# COMPUTE_CLUSTER0_CTL_CFG register map
Vendor: Texas Instruments
Registers are 32-bit, read-write, reset 0x0 unless marked. A register's access mark holds for its fields unless they carry their own. Offsets are as the file gives them; [hi:lo] are bit positions; {n}, {i} and the like mark numbered series.

## COMPUTE_CLUSTER0_CTL_CFG (part 3 of 3)
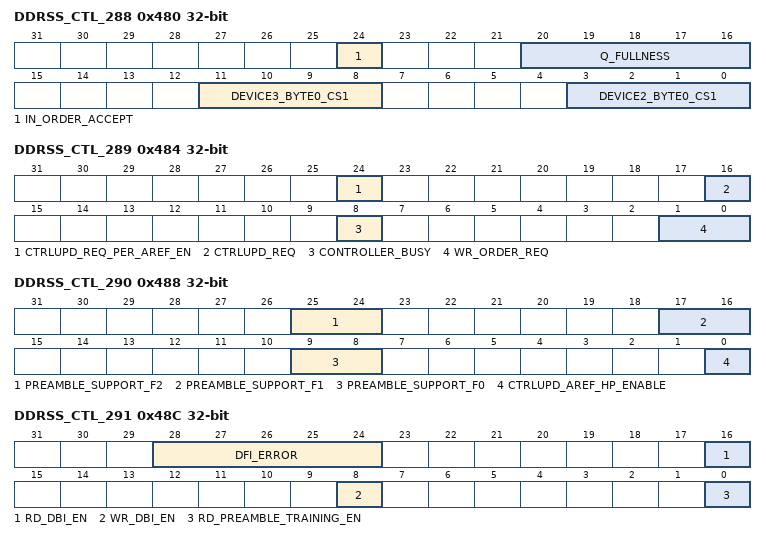
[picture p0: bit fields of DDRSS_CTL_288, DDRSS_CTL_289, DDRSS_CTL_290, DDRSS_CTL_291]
0x480 DDRSS_CTL_288
  [24] IN_ORDER_ACCEPT — Forces the controller to accept commands in the order in which they are placed in the command queue.
  [20:16] Q_FULLNESS — Quantity that determines command queue almost full assertion(q_almost_full).
  [11:8] DEVICE3_BYTE0_CS1 — Defines the byte location of byte0 in the memory datapath for device 3 on chip 1.
  [3:0] DEVICE2_BYTE0_CS1 — Defines the byte location of byte0 in the memory datapath for device 2 on chip 1.
0x484 DDRSS_CTL_289 access per field
  [24] CTRLUPD_REQ_PER_AREF_EN rw — Enable an automatic controller-initiated update (dfi_ctrlupd_req) after every refresh.
  [16] CTRLUPD_REQ wo — Assert the DFI controller-initiated update request signal dfi_ctrlupd_req.
  [8] CONTROLLER_BUSY ro — Indicator that the controller is processing a command.
  [1:0] WR_ORDER_REQ rw — Determines if the controller can re-order write commands from the same source ID and/or the same port.
0x488 DDRSS_CTL_290
  [25:24] PREAMBLE_SUPPORT_F2 — Selection of one or two cycle preamble for read and write burst transfers for frequency copy 2.
  [17:16] PREAMBLE_SUPPORT_F1 — Selection of one or two cycle preamble for read and write burst transfers for frequency copy 1.
  [9:8] PREAMBLE_SUPPORT_F0 — Selection of one or two cycle preamble for read and write burst transfers for frequency copy 0.
  [0] CTRLUPD_AREF_HP_ENABLE — Enable an automatic controller-initiated update (dfi_ctrlupd_req) after every high priority refresh when executing as a subtask request.
0x48C DDRSS_CTL_291 access per field
  [28:24] DFI_ERROR ro — Indicates that the DFI error flag has been asserted.
  [16] RD_DBI_EN rw — Enables controller support of DRAM DBI feature for read data with DDR4 devices.
  [8] WR_DBI_EN rw — Enables controller support of DRAM DBI feature for write data with DDR4 devices.
  [0] RD_PREAMBLE_TRAINING_EN rw — Enable read preamble training during gate training.
0x490 DDRSS_CTL_292 access per field
  [19:0] DFI_ERROR_INFO ro — Holds the encoded DFI error type associated with the DFI_ERROR parameter assertion.
0x494 DDRSS_CTL_293 ro
  [31:0] INT_STATUS_0 — Status of interrupt features in the controller.
0x498 DDRSS_CTL_294 ro
  [12:0] INT_STATUS_1 — Status of interrupt features in the controller.
0x49C DDRSS_CTL_295 wo
  [31:0] INT_ACK_0 — Clear mask of the INT_STATUS parameter.
0x4A0 DDRSS_CTL_296 wo
  [11:0] INT_ACK_1 — Clear mask of the INT_STATUS parameter.
0x4A4 DDRSS_CTL_297
  [31:0] INT_MASK_0 — Mask for the controller_int signal from the INT_STATUS parameter.
0x4A8 DDRSS_CTL_298
  [12:0] INT_MASK_1 — Mask for the controller_int signal from the INT_STATUS parameter.
0x4AC DDRSS_CTL_299 ro
  [31:0] OUT_OF_RANGE_ADDR_0 — Address of command that caused an out-of-range interrupt.
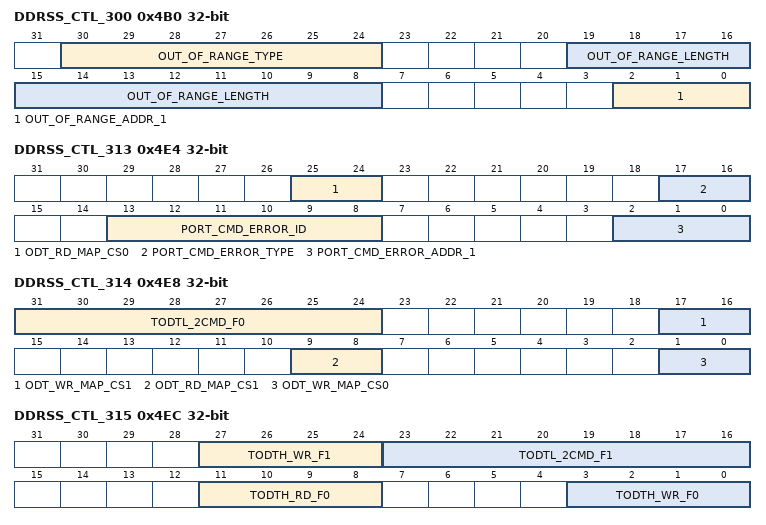
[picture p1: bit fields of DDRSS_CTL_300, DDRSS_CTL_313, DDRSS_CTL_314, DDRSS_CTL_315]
0x4B0 DDRSS_CTL_300 ro
  [30:24] OUT_OF_RANGE_TYPE — Type of command that caused an out-of-range interrupt.
  [19:8] OUT_OF_RANGE_LENGTH — Length of command that caused an out-of-range interrupt.
  [2:0] OUT_OF_RANGE_ADDR_1 — Address of command that caused an out-of-range interrupt.
0x4B4 DDRSS_CTL_301 ro
  [5:0] OUT_OF_RANGE_SOURCE_ID — Source ID of command that caused an out-of-range interrupt.
{0x0+4i} DDRSS_CTL_{i} ro (i=302..305)
  [31:0] BIST_EXP_DATA_{i-302} — Expected data on BIST error.
{0x0+4i} DDRSS_CTL_{i} ro (i=306..309)
  [31:0] BIST_FAIL_DATA_{i-306} — Actual data on BIST error.
0x4D8 DDRSS_CTL_310 ro
  [31:0] BIST_FAIL_ADDR_0 — Address of BIST error.
0x4DC DDRSS_CTL_311 ro
  [2:0] BIST_FAIL_ADDR_1 — Address of BIST error.
0x4E0 DDRSS_CTL_312 ro
  [31:0] PORT_CMD_ERROR_ADDR_0 — Address of command that caused the PORT command error.
0x4E4 DDRSS_CTL_313 access per field
  [25:24] ODT_RD_MAP_CS0 rw — Determines which chip(s) will have termination when a read occurs on chip select 0.
  [17:16] PORT_CMD_ERROR_TYPE ro — Type of error and access type that caused the PORT command error.
  [13:8] PORT_CMD_ERROR_ID ro — Source ID of command that caused the PORT command error.
  [2:0] PORT_CMD_ERROR_ADDR_1 ro — Address of command that caused the PORT command error.
0x4E8 DDRSS_CTL_314
  [31:24] TODTL_2CMD_F0 — Defines the DRAM delay from an ODT de-assertion to the next non-write, non-read command.
  [17:16] ODT_WR_MAP_CS1 — Determines which chip(s) will have termination when a write occurs on chip select 1.
  [9:8] ODT_RD_MAP_CS1 — Determines which chip(s) will have termination when a read occurs on chip select 1.
  [1:0] ODT_WR_MAP_CS0 — Determines which chip(s) will have termination when a write occurs on chip select 0.
0x4EC DDRSS_CTL_315
  [27:24] TODTH_WR_F1 — Defines the DRAM minimum ODT high time after an ODT assertion for a write command.
  [23:16] TODTL_2CMD_F1 — Defines the DRAM delay from an ODT de-assertion to the next non-write, non-read command.
  [11:8] TODTH_RD_F0 — Defines the DRAM minimum ODT high time after an ODT assertion for a read command.
  [3:0] TODTH_WR_F0 — Defines the DRAM minimum ODT high time after an ODT assertion for a write command.
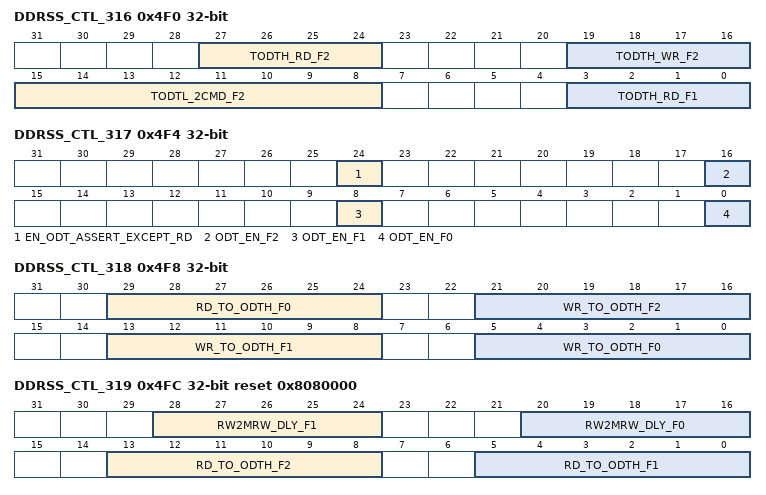
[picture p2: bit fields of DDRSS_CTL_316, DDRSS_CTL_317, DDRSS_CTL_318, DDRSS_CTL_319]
0x4F0 DDRSS_CTL_316
  [27:24] TODTH_RD_F2 — Defines the DRAM minimum ODT high time after an ODT assertion for a read command.
  [19:16] TODTH_WR_F2 — Defines the DRAM minimum ODT high time after an ODT assertion for a write command.
  [15:8] TODTL_2CMD_F2 — Defines the DRAM delay from an ODT de-assertion to the next non-write, non-read command.
  [3:0] TODTH_RD_F1 — Defines the DRAM minimum ODT high time after an ODT assertion for a read command.
0x4F4 DDRSS_CTL_317
  [24] EN_ODT_ASSERT_EXCEPT_RD — Enable controller to assert ODT at all times except during reads.
  [16] ODT_EN_F2 — Enable support of DRAM ODT.
  [8] ODT_EN_F1 — Enable support of DRAM ODT.
  [0] ODT_EN_F0 — Enable support of DRAM ODT.
0x4F8 DDRSS_CTL_318
  [29:24] RD_TO_ODTH_F0 — Defines the delay from a read command to ODT assertion.
  [21:16] WR_TO_ODTH_F2 — Defines the delay from a write command to ODT assertion.
  [13:8] WR_TO_ODTH_F1 — Defines the delay from a write command to ODT assertion.
  [5:0] WR_TO_ODTH_F0 — Defines the delay from a write command to ODT assertion.
0x4FC DDRSS_CTL_319 reset 0x8080000
  [28:24] RW2MRW_DLY_F1 — Additional delay to insert between read or write and mode_reg_write.
  [20:16] RW2MRW_DLY_F0 — Additional delay to insert between read or write and mode_reg_write.
  [13:8] RD_TO_ODTH_F2 — Defines the delay from a read command to ODT assertion.
  [5:0] RD_TO_ODTH_F1 — Defines the delay from a read command to ODT assertion.
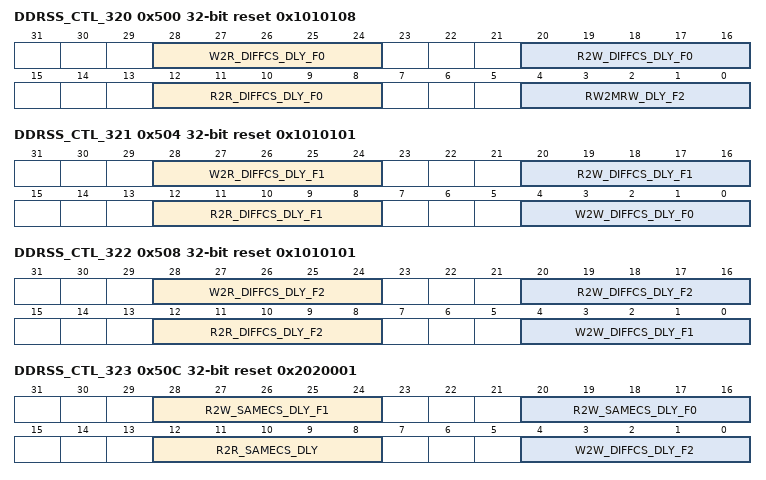
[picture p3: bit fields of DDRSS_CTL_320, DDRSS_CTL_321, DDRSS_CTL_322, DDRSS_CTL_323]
0x500 DDRSS_CTL_320 reset 0x1010108
  [28:24] W2R_DIFFCS_DLY_F0 — Additional delay to insert between writes and reads to different chip selects.
  [20:16] R2W_DIFFCS_DLY_F0 — Additional delay to insert between reads and writes to different chip selects.
  [12:8] R2R_DIFFCS_DLY_F0 — Additional delay to insert between reads to different chip selects.
  [4:0] RW2MRW_DLY_F2 — Additional delay to insert between read or write and mode_reg_write.
0x504 DDRSS_CTL_321 reset 0x1010101
  [28:24] W2R_DIFFCS_DLY_F1 — Additional delay to insert between writes and reads to different chip selects.
  [20:16] R2W_DIFFCS_DLY_F1 — Additional delay to insert between reads and writes to different chip selects.
  [12:8] R2R_DIFFCS_DLY_F1 — Additional delay to insert between reads to different chip selects.
  [4:0] W2W_DIFFCS_DLY_F0 — Additional delay to insert between writes to different chip selects.
0x508 DDRSS_CTL_322 reset 0x1010101
  [28:24] W2R_DIFFCS_DLY_F2 — Additional delay to insert between writes and reads to different chip selects.
  [20:16] R2W_DIFFCS_DLY_F2 — Additional delay to insert between reads and writes to different chip selects.
  [12:8] R2R_DIFFCS_DLY_F2 — Additional delay to insert between reads to different chip selects.
  [4:0] W2W_DIFFCS_DLY_F1 — Additional delay to insert between writes to different chip selects.
0x50C DDRSS_CTL_323 reset 0x2020001
  [28:24] R2W_SAMECS_DLY_F1 — Additional delay to insert between reads and writes to the same chip select.
  [20:16] R2W_SAMECS_DLY_F0 — Additional delay to insert between reads and writes to the same chip select.
  [12:8] R2R_SAMECS_DLY — Additional delay to insert between two reads to the same chip select.
  [4:0] W2W_DIFFCS_DLY_F2 — Additional delay to insert between writes to different chip selects.
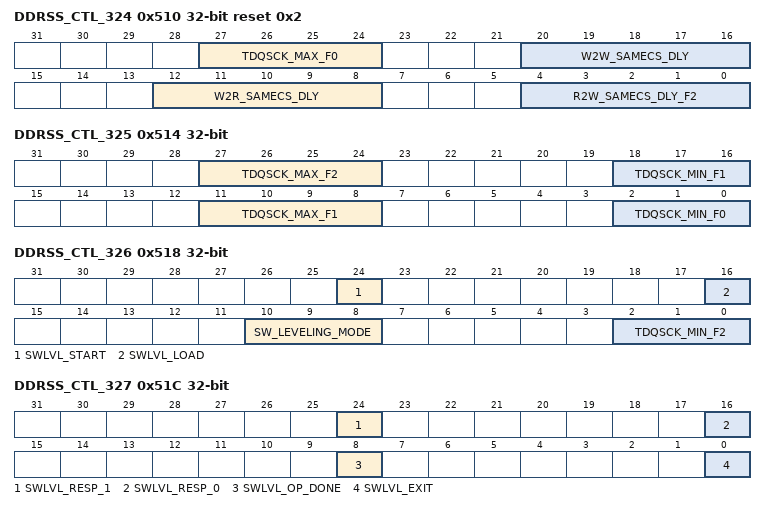
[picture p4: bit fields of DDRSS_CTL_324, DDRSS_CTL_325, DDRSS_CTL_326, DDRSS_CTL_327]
0x510 DDRSS_CTL_324 reset 0x2
  [27:24] TDQSCK_MAX_F0 — Additional delay needed for tDQSCK.
  [20:16] W2W_SAMECS_DLY — Additional delay to insert between two writes to the same chip select.
  [12:8] W2R_SAMECS_DLY — Additional delay to insert between writes and reads to the same chip select.
  [4:0] R2W_SAMECS_DLY_F2 — Additional delay to insert between reads and writes to the same chip select.
0x514 DDRSS_CTL_325
  [27:24] TDQSCK_MAX_F2 — Additional delay needed for tDQSCK.
  [18:16] TDQSCK_MIN_F1 — Additional delay needed for tDQSCK.
  [11:8] TDQSCK_MAX_F1 — Additional delay needed for tDQSCK.
  [2:0] TDQSCK_MIN_F0 — Additional delay needed for tDQSCK.
0x518 DDRSS_CTL_326 access per field
  [24] SWLVL_START wo — User request to initiate software leveling of type in the SW_LEVELING_MODE parameter.
  [16] SWLVL_LOAD wo — User request to load delays and execute software leveling.
  [10:8] SW_LEVELING_MODE rw — Defines the leveling operation for software leveling.
  [2:0] TDQSCK_MIN_F2 rw — Additional delay needed for tDQSCK.
0x51C DDRSS_CTL_327 access per field
  [24] SWLVL_RESP_1 ro — Leveling response for data slice 1.
  [16] SWLVL_RESP_0 ro — Leveling response for data slice 0.
  [8] SWLVL_OP_DONE ro — Signals that software leveling is currently in progress.
  [0] SWLVL_EXIT wo — User request to exit software leveling.
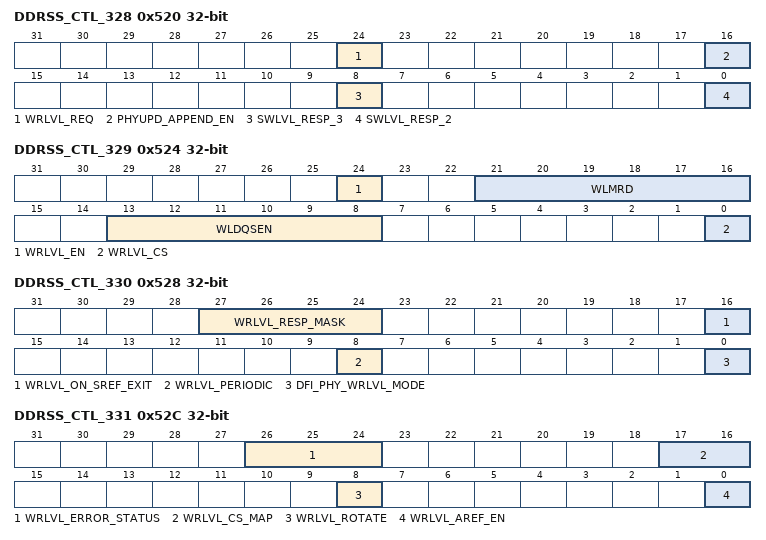
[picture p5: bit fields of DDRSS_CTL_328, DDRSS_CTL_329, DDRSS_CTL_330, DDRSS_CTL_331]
0x520 DDRSS_CTL_328 access per field
  [24] WRLVL_REQ wo — User request to initiate write leveling.
  [16] PHYUPD_APPEND_EN rw — Specifies if a PHY update will be run prior to completing a training sequence.
  [8] SWLVL_RESP_3 ro — Leveling response for data slice 3.
  [0] SWLVL_RESP_2 ro — Leveling response for data slice 2.
0x524 DDRSS_CTL_329
  [24] WRLVL_EN — Enable the MC write leveling module.
  [21:16] WLMRD — Delay from issuing MRS to first write leveling strobe.
  [13:8] WLDQSEN — Delay from issuing MRS to first DQS strobe for write leveling.
  [0] WRLVL_CS — Specifies the target chip select for the write leveling operation initiated through the WRLVL_REQ parameter.
0x528 DDRSS_CTL_330
  [27:24] WRLVL_RESP_MASK — Mask for the dfi_wrlvl_resp signal during write leveling.
  [16] WRLVL_ON_SREF_EXIT — Enables automatic write leveling on a self-refresh exit.
  [8] WRLVL_PERIODIC — Enables the use of the dfi_lvl_periodic signal during write leveling.
  [0] DFI_PHY_WRLVL_MODE — Specifies the PHY support for DFI write leveling.
0x52C DDRSS_CTL_331 access per field
  [26:24] WRLVL_ERROR_STATUS ro — Holds the error associated with the write level error interrupt.
  [17:16] WRLVL_CS_MAP rw — Defines the chip select map for write leveling operations.
  [8] WRLVL_ROTATE rw — Enables rotational CS for interval write leveling.
  [0] WRLVL_AREF_EN rw — Enables refreshes and other non-data commands to execute in the middle of write leveling.
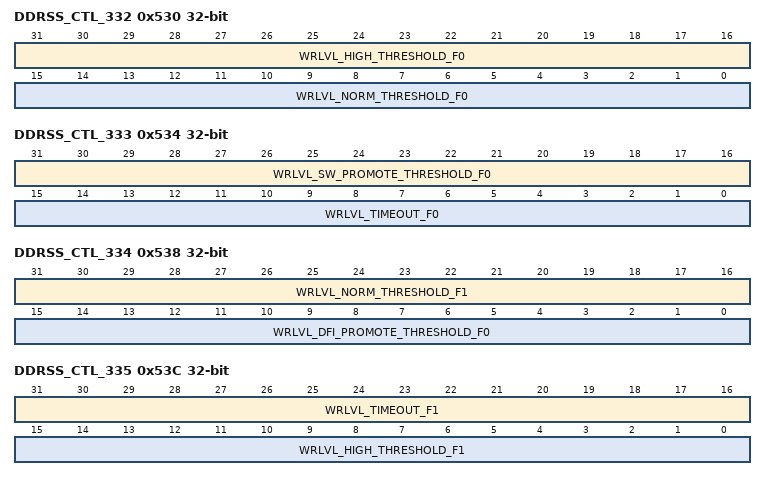
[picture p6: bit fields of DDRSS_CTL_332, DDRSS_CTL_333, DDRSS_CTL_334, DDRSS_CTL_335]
0x530 DDRSS_CTL_332
  [31:16] WRLVL_HIGH_THRESHOLD_F0 — Write leveling high threshold number of long counts until the high priority request is asserted.
  [15:0] WRLVL_NORM_THRESHOLD_F0 — Write leveling normal threshold number of long counts until the normal priority request is asserted.
0x534 DDRSS_CTL_333
  [31:16] WRLVL_SW_PROMOTE_THRESHOLD_F0 — Write leveling promotion number of long counts until the high priority request is asserted.
  [15:0] WRLVL_TIMEOUT_F0 — Write leveling timeout number of long counts until the timeout is asserted.
0x538 DDRSS_CTL_334
  [31:16] WRLVL_NORM_THRESHOLD_F1 — Write leveling normal threshold number of long counts until the normal priority request is asserted.
  [15:0] WRLVL_DFI_PROMOTE_THRESHOLD_F0 — Write leveling promotion number of long counts until the high priority request is asserted.
0x53C DDRSS_CTL_335
  [31:16] WRLVL_TIMEOUT_F1 — Write leveling timeout number of long counts until the timeout is asserted.
  [15:0] WRLVL_HIGH_THRESHOLD_F1 — Write leveling high threshold number of long counts until the high priority request is asserted.
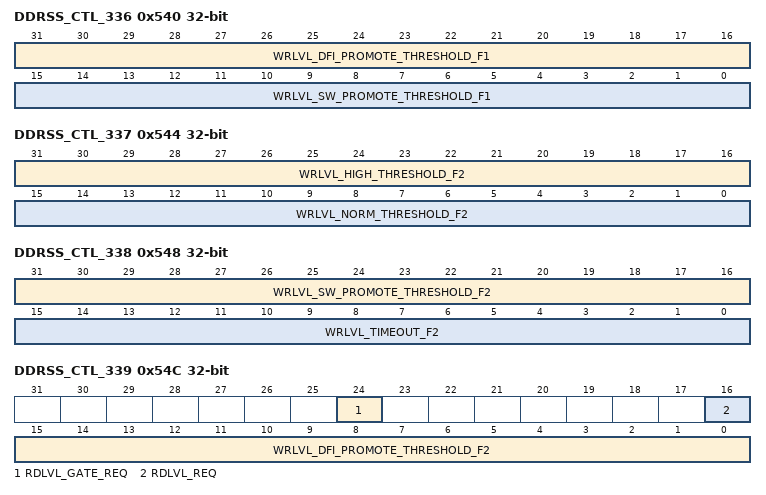
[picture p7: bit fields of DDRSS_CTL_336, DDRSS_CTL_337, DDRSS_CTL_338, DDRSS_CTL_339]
0x540 DDRSS_CTL_336
  [31:16] WRLVL_DFI_PROMOTE_THRESHOLD_F1 — Write leveling promotion number of long counts until the high priority request is asserted.
  [15:0] WRLVL_SW_PROMOTE_THRESHOLD_F1 — Write leveling promotion number of long counts until the high priority request is asserted.
0x544 DDRSS_CTL_337
  [31:16] WRLVL_HIGH_THRESHOLD_F2 — Write leveling high threshold number of long counts until the high priority request is asserted.
  [15:0] WRLVL_NORM_THRESHOLD_F2 — Write leveling normal threshold number of long counts until the normal priority request is asserted.
0x548 DDRSS_CTL_338
  [31:16] WRLVL_SW_PROMOTE_THRESHOLD_F2 — Write leveling promotion number of long counts until the high priority request is asserted.
  [15:0] WRLVL_TIMEOUT_F2 — Write leveling timeout number of long counts until the timeout is asserted.
0x54C DDRSS_CTL_339 access per field
  [24] RDLVL_GATE_REQ wo — User request to initiate gate training.
  [16] RDLVL_REQ wo — User request to initiate data eye training.
  [15:0] WRLVL_DFI_PROMOTE_THRESHOLD_F2 rw — Write leveling promotion number of long counts until the high priority request is asserted.
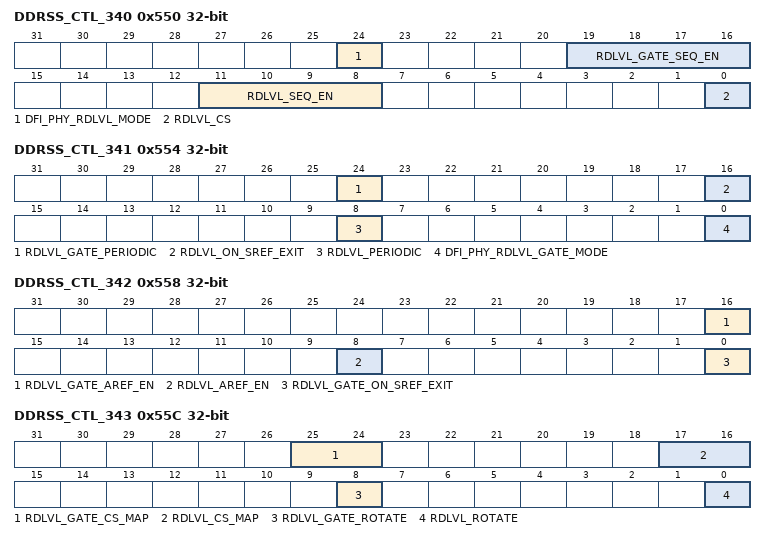
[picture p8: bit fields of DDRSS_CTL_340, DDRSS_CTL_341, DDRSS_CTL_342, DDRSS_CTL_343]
0x550 DDRSS_CTL_340
  [24] DFI_PHY_RDLVL_MODE — Specifies the PHY support for DFI data eye training.
  [19:16] RDLVL_GATE_SEQ_EN — Specifies the pattern, format and MPR for gate training.
  [11:8] RDLVL_SEQ_EN — Specifies the pattern, format and MPR for data eye training.
  [0] RDLVL_CS — Specifies the target chip select for the data eye training operation initiated through the RDLVL_REQ parameter or the gate training operation initiated through the RDLVL_GATE_REQ parameter.
0x554 DDRSS_CTL_341
  [24] RDLVL_GATE_PERIODIC — Enables the use of the dfi_lvl_periodic signal during gate training.
  [16] RDLVL_ON_SREF_EXIT — Enables automatic data eye training on a self-refresh exit.
  [8] RDLVL_PERIODIC — Enables the use of the dfi_lvl_periodic signal during data eye training.
  [0] DFI_PHY_RDLVL_GATE_MODE — Specifies the PHY support for DFI gate training.
0x558 DDRSS_CTL_342
  [16] RDLVL_GATE_AREF_EN — Enables refreshes and other non-data commands to execute in the middle of gate training.
  [8] RDLVL_AREF_EN — Enables refreshes and other non-data commands to execute in the middle of data eye training.
  [0] RDLVL_GATE_ON_SREF_EXIT — Enables automatic gate training on a self-refresh exit.
0x55C DDRSS_CTL_343
  [25:24] RDLVL_GATE_CS_MAP — Defines the chip select map for gate training operations.
  [17:16] RDLVL_CS_MAP — Defines the chip select map for data eye training operations.
  [8] RDLVL_GATE_ROTATE — Enables rotational CS for interval gate training.
  [0] RDLVL_ROTATE — Enables rotational CS for interval data eye training.
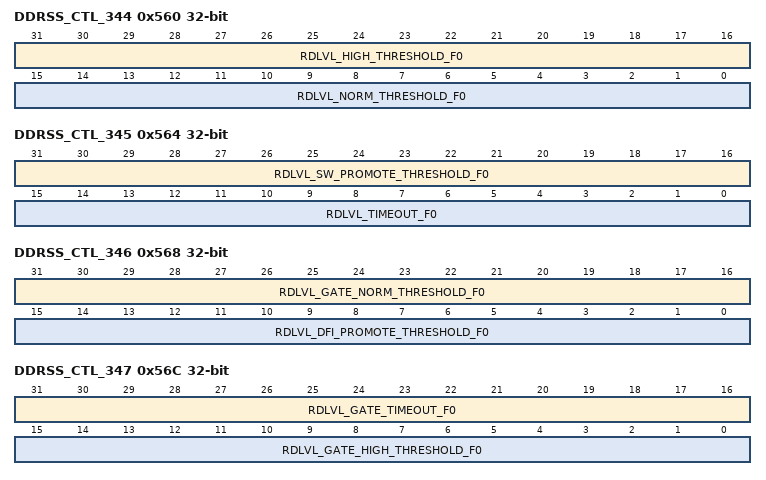
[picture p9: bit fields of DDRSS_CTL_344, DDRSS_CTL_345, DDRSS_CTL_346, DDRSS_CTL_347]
0x560 DDRSS_CTL_344
  [31:16] RDLVL_HIGH_THRESHOLD_F0 — Read leveling high threshold number of long counts until the high priority request is asserted.
  [15:0] RDLVL_NORM_THRESHOLD_F0 — Read leveling normal threshold number of long counts until the normal priority request is asserted.
0x564 DDRSS_CTL_345
  [31:16] RDLVL_SW_PROMOTE_THRESHOLD_F0 — Read leveling promotion number of long counts until the high priority request is asserted.
  [15:0] RDLVL_TIMEOUT_F0 — Read leveling timeout number of long counts until the timeout is asserted.
0x568 DDRSS_CTL_346
  [31:16] RDLVL_GATE_NORM_THRESHOLD_F0 — Gate training normal threshold number of long counts until the normal priority request is asserted.
  [15:0] RDLVL_DFI_PROMOTE_THRESHOLD_F0 — Read leveling promotion number of long counts until the high priority request is asserted.
0x56C DDRSS_CTL_347
  [31:16] RDLVL_GATE_TIMEOUT_F0 — Gate training timeout number of long counts until the timeout is asserted.
  [15:0] RDLVL_GATE_HIGH_THRESHOLD_F0 — Gate training high threshold number of long counts until the high priority request is asserted.
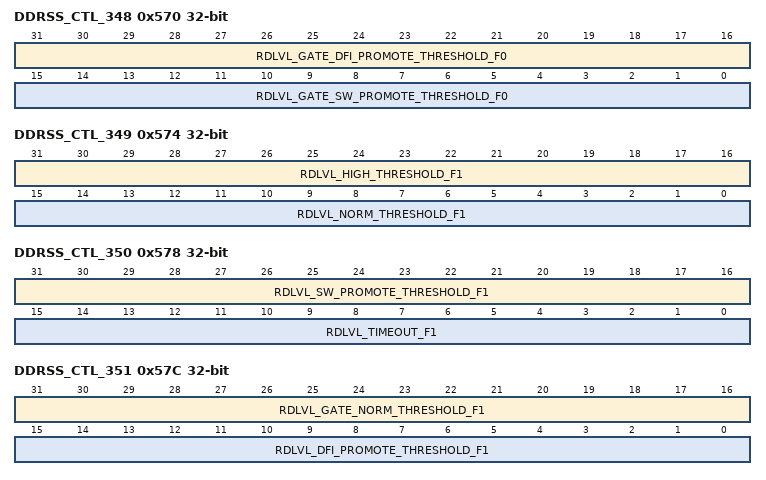
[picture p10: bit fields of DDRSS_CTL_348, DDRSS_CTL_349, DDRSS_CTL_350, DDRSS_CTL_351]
0x570 DDRSS_CTL_348
  [31:16] RDLVL_GATE_DFI_PROMOTE_THRESHOLD_F0 — Gate training promotion number of long counts until the high priority request is asserted.
  [15:0] RDLVL_GATE_SW_PROMOTE_THRESHOLD_F0 — Gate training promotion number of long counts until the high priority request is asserted.
0x574 DDRSS_CTL_349
  [31:16] RDLVL_HIGH_THRESHOLD_F1 — Read leveling high threshold number of long counts until the high priority request is asserted.
  [15:0] RDLVL_NORM_THRESHOLD_F1 — Read leveling normal threshold number of long counts until the normal priority request is asserted.
0x578 DDRSS_CTL_350
  [31:16] RDLVL_SW_PROMOTE_THRESHOLD_F1 — Read leveling promotion number of long counts until the high priority request is asserted.
  [15:0] RDLVL_TIMEOUT_F1 — Read leveling timeout number of long counts until the timeout is asserted.
0x57C DDRSS_CTL_351
  [31:16] RDLVL_GATE_NORM_THRESHOLD_F1 — Gate training normal threshold number of long counts until the normal priority request is asserted.
  [15:0] RDLVL_DFI_PROMOTE_THRESHOLD_F1 — Read leveling promotion number of long counts until the high priority request is asserted.
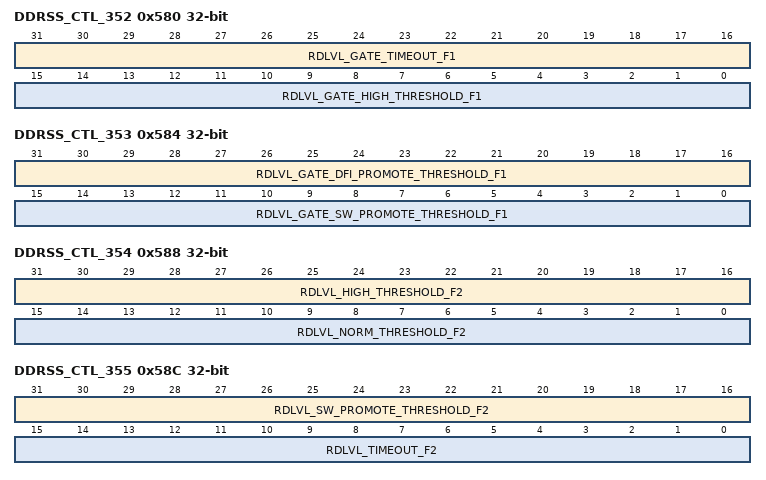
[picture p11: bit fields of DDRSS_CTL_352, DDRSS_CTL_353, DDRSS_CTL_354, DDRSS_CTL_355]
0x580 DDRSS_CTL_352
  [31:16] RDLVL_GATE_TIMEOUT_F1 — Gate training timeout number of long counts until the timeout is asserted.
  [15:0] RDLVL_GATE_HIGH_THRESHOLD_F1 — Gate training high threshold number of long counts until the high priority request is asserted.
0x584 DDRSS_CTL_353
  [31:16] RDLVL_GATE_DFI_PROMOTE_THRESHOLD_F1 — Gate training promotion number of long counts until the high priority request is asserted.
  [15:0] RDLVL_GATE_SW_PROMOTE_THRESHOLD_F1 — Gate training promotion number of long counts until the high priority request is asserted.
0x588 DDRSS_CTL_354
  [31:16] RDLVL_HIGH_THRESHOLD_F2 — Read leveling high threshold number of long counts until the high priority request is asserted.
  [15:0] RDLVL_NORM_THRESHOLD_F2 — Read leveling normal threshold number of long counts until the normal priority request is asserted.
0x58C DDRSS_CTL_355
  [31:16] RDLVL_SW_PROMOTE_THRESHOLD_F2 — Read leveling promotion number of long counts until the high priority request is asserted.
  [15:0] RDLVL_TIMEOUT_F2 — Read leveling timeout number of long counts until the timeout is asserted.
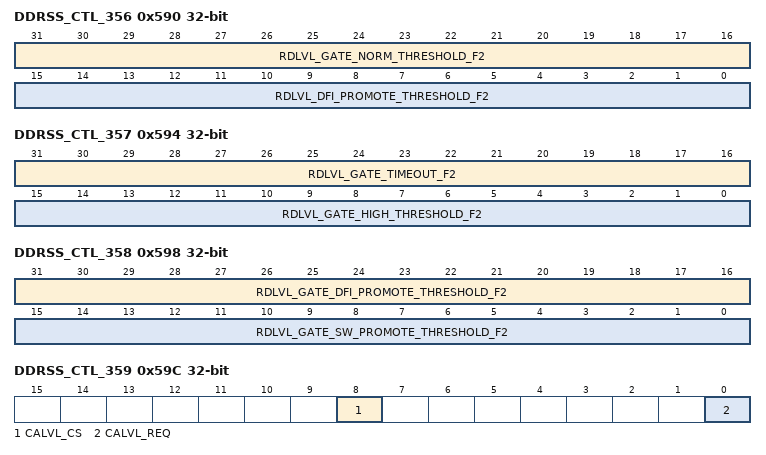
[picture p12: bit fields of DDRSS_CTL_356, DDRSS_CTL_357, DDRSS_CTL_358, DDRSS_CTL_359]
0x590 DDRSS_CTL_356
  [31:16] RDLVL_GATE_NORM_THRESHOLD_F2 — Gate training normal threshold number of long counts until the normal priority request is asserted.
  [15:0] RDLVL_DFI_PROMOTE_THRESHOLD_F2 — Read leveling promotion number of long counts until the high priority request is asserted.
0x594 DDRSS_CTL_357
  [31:16] RDLVL_GATE_TIMEOUT_F2 — Gate training timeout number of long counts until the timeout is asserted.
  [15:0] RDLVL_GATE_HIGH_THRESHOLD_F2 — Gate training high threshold number of long counts until the high priority request is asserted.
0x598 DDRSS_CTL_358
  [31:16] RDLVL_GATE_DFI_PROMOTE_THRESHOLD_F2 — Gate training promotion number of long counts until the high priority request is asserted.
  [15:0] RDLVL_GATE_SW_PROMOTE_THRESHOLD_F2 — Gate training promotion number of long counts until the high priority request is asserted.
0x59C DDRSS_CTL_359 access per field
  [8] CALVL_CS rw — Specifies the target chip select for the CA training operation initiated through the CALVL_REQ parameter.
  [0] CALVL_REQ wo — User request to initiate CA training.
0x5A0 DDRSS_CTL_360
  [19:0] CALVL_PAT_0 — CA Training pattern 0 driven on the CA bus during a calibration command.
0x5A4 DDRSS_CTL_361
  [19:0] CALVL_BG_PAT_0 — CA Training pattern 0 driven on the CA bus before and after a calibration command.
0x5A8 DDRSS_CTL_362
  [19:0] CALVL_PAT_1 — CA Training pattern 1 driven on the CA bus during a calibration command.
0x5AC DDRSS_CTL_363
  [19:0] CALVL_BG_PAT_1 — CA Training pattern 1 driven on the CA bus before and after a calibration command.
0x5B0 DDRSS_CTL_364
  [19:0] CALVL_PAT_2 — CA Training pattern 2 driven on the CA bus during a calibration command.
0x5B4 DDRSS_CTL_365
  [19:0] CALVL_BG_PAT_2 — CA Training pattern 2 driven on the CA bus before and after a calibration command.
0x5B8 DDRSS_CTL_366
  [19:0] CALVL_PAT_3 — CA Training pattern 3 driven on the CA bus during a calibration command.
0x5BC DDRSS_CTL_367
  [19:0] CALVL_BG_PAT_3 — CA Training pattern 3 driven on the CA bus before and after a calibration command.
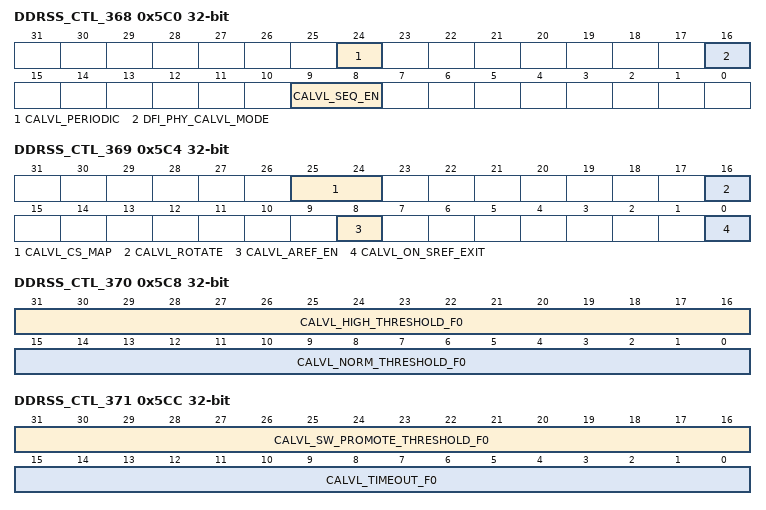
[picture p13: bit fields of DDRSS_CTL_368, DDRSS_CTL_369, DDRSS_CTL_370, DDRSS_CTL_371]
0x5C0 DDRSS_CTL_368
  [24] CALVL_PERIODIC — Enables the use of the dfi_lvl_periodic signal during CA training.
  [16] DFI_PHY_CALVL_MODE — Specifies the PHY support for DFI CA training.
  [9:8] CALVL_SEQ_EN — Specifies which CA training patterns will be used.
0x5C4 DDRSS_CTL_369
  [25:24] CALVL_CS_MAP — Defines the chip select map for CA training operations.
  [16] CALVL_ROTATE — Enables rotational CS for interval CA training.
  [8] CALVL_AREF_EN — Enables refreshes and other non-data commands to execute in the middle of CA training.
  [0] CALVL_ON_SREF_EXIT — Enables automatic CA training on a self-refresh exit.
0x5C8 DDRSS_CTL_370
  [31:16] CALVL_HIGH_THRESHOLD_F0 — CA training high threshold number of long counts until the high priority request is asserted.
  [15:0] CALVL_NORM_THRESHOLD_F0 — CA training normal threshold number of long counts until the normal priority request is asserted.
0x5CC DDRSS_CTL_371
  [31:16] CALVL_SW_PROMOTE_THRESHOLD_F0 — CA training promotion number of long counts until the high priority request is asserted.
  [15:0] CALVL_TIMEOUT_F0 — CA training timeout number of long counts until the timeout is asserted.
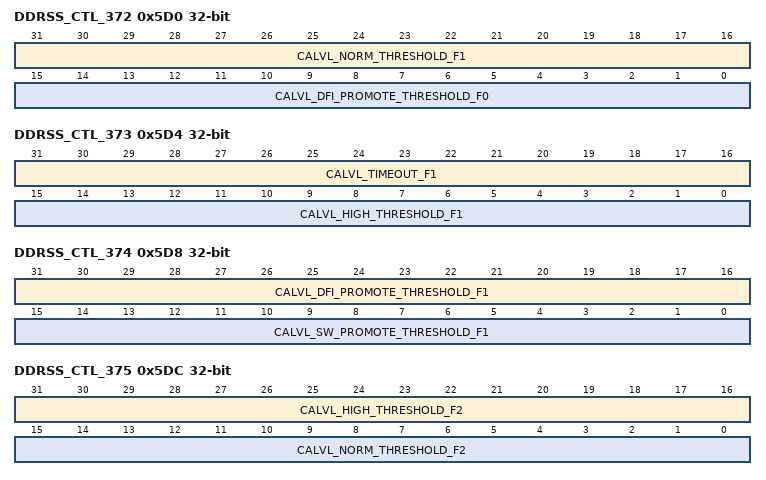
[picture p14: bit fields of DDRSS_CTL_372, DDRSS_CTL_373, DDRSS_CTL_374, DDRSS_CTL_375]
0x5D0 DDRSS_CTL_372
  [31:16] CALVL_NORM_THRESHOLD_F1 — CA training normal threshold number of long counts until the normal priority request is asserted.
  [15:0] CALVL_DFI_PROMOTE_THRESHOLD_F0 — CA training promotion number of long counts until the high priority request is asserted.
0x5D4 DDRSS_CTL_373
  [31:16] CALVL_TIMEOUT_F1 — CA training timeout number of long counts until the timeout is asserted.
  [15:0] CALVL_HIGH_THRESHOLD_F1 — CA training high threshold number of long counts until the high priority request is asserted.
0x5D8 DDRSS_CTL_374
  [31:16] CALVL_DFI_PROMOTE_THRESHOLD_F1 — CA training promotion number of long counts until the high priority request is asserted.
  [15:0] CALVL_SW_PROMOTE_THRESHOLD_F1 — CA training promotion number of long counts until the high priority request is asserted.
0x5DC DDRSS_CTL_375
  [31:16] CALVL_HIGH_THRESHOLD_F2 — CA training high threshold number of long counts until the high priority request is asserted.
  [15:0] CALVL_NORM_THRESHOLD_F2 — CA training normal threshold number of long counts until the normal priority request is asserted.
0x5E0 DDRSS_CTL_376
  [31:16] CALVL_SW_PROMOTE_THRESHOLD_F2 — CA training promotion number of long counts until the high priority request is asserted.
  [15:0] CALVL_TIMEOUT_F2 — CA training timeout number of long counts until the timeout is asserted.
0x5E4 DDRSS_CTL_377
  [24] AXI0_FIXED_PORT_PRIORITY_ENABLE — Defines the priority control for AXI port 0 as per-port or per-command.
  [16] AXI0_ALL_STROBES_USED_ENABLE — Enables use of the AWALLSTRB signal for AXI port 0.
  [15:0] CALVL_DFI_PROMOTE_THRESHOLD_F2 — CA training promotion number of long counts until the high priority request is asserted.
0x5E8 DDRSS_CTL_378
  [10:8] AXI0_W_PRIORITY — Priority of write commands from AXI port 0.
  [2:0] AXI0_R_PRIORITY — Priority of read commands from AXI port 0.
0x5EC DDRSS_CTL_379 ro
  [31:0] PARITY_ERROR_ADDRESS_0 — Address of the AXI command that resulted in the parity error.
0x5F0 DDRSS_CTL_380 ro
  [28:16] PARITY_ERROR_BUS_CHANNEL — Reports the AXI field that resulted in the parity error.
  [13:8] PARITY_ERROR_MASTER_ID — Port ID and Master ID of the AXI command that resulted in the parity error.
  [2:0] PARITY_ERROR_ADDRESS_1 — Address of the AXI command that resulted in the parity error.
{0x0+4i} DDRSS_CTL_{i} ro (i=381..384)
  [31:0] PARITY_ERROR_WRITE_DATA_{i-381} — Write data of the AXI command that resulted in the parity error.
0x604 DDRSS_CTL_385 ro
  [24] MEM_RST_VALID — Register access to mem_rst_valid signal.
  [17:16] CKE_STATUS — Register access to cke_status signal.
  [15:0] PARITY_ERROR_WRITE_DATA_PARITY_VECTOR — Write data parity vector associated with the AXI command that resulted in the parity error.
0x608 DDRSS_CTL_386 access per field
  [30:24] TDFI_PHY_WRLAT ro — Holds the calculated DFI tPHY_WRLAT timing parameter (in DFI PHY clocks), the maximum cycles between a write command and a dfi_wrdata_en assertion.
  [23:16] DLL_RST_ADJ_DLY rw — Minimum cycles after setting master delay in DLL until the DLL reset signal dll_rst_n may be asserted.
  [15:0] DLL_RST_DELAY rw — Minimum cycles required for DLL reset signal dll_rst_n to be held.
0x60C DDRSS_CTL_387 access per field reset 0x6060600
  [30:24] TDFI_PHY_RDLAT_F2 rw — Defines the DFI tPHY_RDLAT timing parameter (in DFI PHY clocks), the maximum cycles between a dfi_rddata_en assertion and a dfi_rddata_valid assertion.
  [22:16] TDFI_PHY_RDLAT_F1 rw — Defines the DFI tPHY_RDLAT timing parameter (in DFI PHY clocks), the maximum cycles between a dfi_rddata_en assertion and a dfi_rddata_valid assertion.
  [14:8] TDFI_PHY_RDLAT_F0 rw — Defines the DFI tPHY_RDLAT timing parameter (in DFI PHY clocks), the maximum cycles between a dfi_rddata_en assertion and a dfi_rddata_valid assertion.
  [6:0] UPDATE_ERROR_STATUS ro — Identifies the source of any DFI MC-initiated or PHY-initiated update errors.
0x610 DDRSS_CTL_388 access per field
  [23:16] TDFI_CTRLUPD_MIN rw — Defines the DFI tCTRLUPD_MIN timing parameter (in DFI clocks), the minimum cycles that dfi_ctrlupd_req must be asserted.
  [9:8] DRAM_CLK_DISABLE rw — Set value for the dfi_dram_clk_disable signal.
  [6:0] TDFI_RDDATA_EN ro — Holds the calculated DFI tRDDATA_EN timing parameter (in DFI PHY clocks), the maximum cycles between a read command and a dfi_rddata_en assertion.
0x614 DDRSS_CTL_389
  [20:0] TDFI_CTRLUPD_MAX_F0 — Defines the DFI tCTRLUPD_MAX timing parameter (in DFI clocks), the maximum cycles that dfi_ctrlupd_req can be asserted.
{0x0+4i} DDRSS_CTL_{i} (i=390..393)
  [31:0] TDFI_PHYUPD_TYPE{i-390}_F0 — Defines the DFI tPHYUPD_TYPE{i-390} timing parameter (in DFI clocks), the maximum cycles that dfi_phyupd_req can assert after dfi_phyupd_ack for dfi_phyupd_type {i-390}.
0x628 DDRSS_CTL_394
  [22:0] TDFI_PHYUPD_RESP_F0 — Defines the DFI tPHYUPD_RESP timing parameter (in DFI clocks), the maximum cycles between a dfi_phyupd_req assertion and a dfi_phyupd_ack assertion.
0x62C DDRSS_CTL_395
  [31:0] TDFI_CTRLUPD_INTERVAL_F0 — Defines the DFI tCTRLUPD_INTERVAL timing parameter (in DFI clocks), the maximum cycles between dfi_ctrlupd_req assertions.
0x630 DDRSS_CTL_396
  [14:8] WRLAT_ADJ_F0 — Adjustment value for PHY write timing.
  [6:0] RDLAT_ADJ_F0 — Adjustment value for PHY read timing.
0x634 DDRSS_CTL_397
  [20:0] TDFI_CTRLUPD_MAX_F1 — Defines the DFI tCTRLUPD_MAX timing parameter (in DFI clocks), the maximum cycles that dfi_ctrlupd_req can be asserted.
{0x0+4i} DDRSS_CTL_{i} (i=398..401)
  [31:0] TDFI_PHYUPD_TYPE{i-398}_F1 — Defines the DFI tPHYUPD_TYPE{i-398} timing parameter (in DFI clocks), the maximum cycles that dfi_phyupd_req can assert after dfi_phyupd_ack for dfi_phyupd_type {i-398}.
0x648 DDRSS_CTL_402
  [22:0] TDFI_PHYUPD_RESP_F1 — Defines the DFI tPHYUPD_RESP timing parameter (in DFI clocks), the maximum cycles between a dfi_phyupd_req assertion and a dfi_phyupd_ack assertion.
0x64C DDRSS_CTL_403
  [31:0] TDFI_CTRLUPD_INTERVAL_F1 — Defines the DFI tCTRLUPD_INTERVAL timing parameter (in DFI clocks), the maximum cycles between dfi_ctrlupd_req assertions.
0x650 DDRSS_CTL_404
  [14:8] WRLAT_ADJ_F1 — Adjustment value for PHY write timing.
  [6:0] RDLAT_ADJ_F1 — Adjustment value for PHY read timing.
0x654 DDRSS_CTL_405
  [20:0] TDFI_CTRLUPD_MAX_F2 — Defines the DFI tCTRLUPD_MAX timing parameter (in DFI clocks), the maximum cycles that dfi_ctrlupd_req can be asserted.
{0x0+4i} DDRSS_CTL_{i} (i=406..409)
  [31:0] TDFI_PHYUPD_TYPE{i-406}_F2 — Defines the DFI tPHYUPD_TYPE{i-406} timing parameter (in DFI clocks), the maximum cycles that dfi_phyupd_req can assert after dfi_phyupd_ack for dfi_phyupd_type {i-406}.
0x668 DDRSS_CTL_410
  [22:0] TDFI_PHYUPD_RESP_F2 — Defines the DFI tPHYUPD_RESP timing parameter (in DFI clocks), the maximum cycles between a dfi_phyupd_req assertion and a dfi_phyupd_ack assertion.
0x66C DDRSS_CTL_411
  [31:0] TDFI_CTRLUPD_INTERVAL_F2 — Defines the DFI tCTRLUPD_INTERVAL timing parameter (in DFI clocks), the maximum cycles between dfi_ctrlupd_req assertions.
0x670 DDRSS_CTL_412 reset 0x2020000
  [27:24] TDFI_CTRL_DELAY_F1 — Defines the DFI tCTRL_DELAY timing parameter (in DFI clocks), the delay between a DFI command change and a memory command.
  [19:16] TDFI_CTRL_DELAY_F0 — Defines the DFI tCTRL_DELAY timing parameter (in DFI clocks), the delay between a DFI command change and a memory command.
  [14:8] WRLAT_ADJ_F2 — Adjustment value for PHY write timing.
  [6:0] RDLAT_ADJ_F2 — Adjustment value for PHY read timing.
0x674 DDRSS_CTL_413 reset 0x2
  [31:24] TDFI_WRLVL_EN — Defines the DFI tWRLVL_EN timing parameter (in DFI clocks), the minimum cycles from a dfi_wrlvl_en assertion to the first dfi_wrlvl_strobe assertion.
  [19:16] TDFI_DRAM_CLK_ENABLE — Defines the DFI tDRAM_CLK_ENABLE timing parameter (in DFI clocks), the delay between a dfi_dram_clk_disable de-assertion and the memory clock enable.
  [11:8] TDFI_DRAM_CLK_DISABLE — Defines the DFI tDRAM_CLK_DISABLE timing parameter (in DFI clocks), the delay between a dfi_dram_clock_disable assertion and the memory clock disable.
  [3:0] TDFI_CTRL_DELAY_F2 — Defines the DFI tCTRL_DELAY timing parameter (in DFI clocks), the delay between a DFI command change and a memory command.
0x678 DDRSS_CTL_414
  [9:0] TDFI_WRLVL_WW — Defines the DFI tWRLVL_WW timing parameter (in DFI clocks), the minimum cycles between dfi_wrlvl_strobe assertions.
0x67C DDRSS_CTL_415
  [31:0] TDFI_WRLVL_RESP — Defines the DFI tWRLVL_RESP timing parameter (in DFI clocks), the maximum cycles between a dfi_wrlvl_req assertion and a dfi_wrlvl_en assertion.
0x680 DDRSS_CTL_416
  [31:0] TDFI_WRLVL_MAX — Defines the DFI tWRLVL_MAX timing parameter (in DFI clocks), the maximum cycles between a dfi_wrlvl_en assertion and a valid dfi_wrlvl_resp.
0x684 DDRSS_CTL_417
  [17:8] TDFI_RDLVL_RR — Defines the DFI tRDLVL_RR timing parameter (in DFI clocks), the minimum cycles between read commands.
  [7:0] TDFI_RDLVL_EN — Defines the DFI tRDLVL_EN timing parameter (in DFI clocks), the minimum cycles from a dfi_rdlvl_en or dfi_rdlvl_gate_en assertion to the first read or MRR.
0x688 DDRSS_CTL_418
  [31:0] TDFI_RDLVL_RESP — Defines the DFI tRDLVL_RESP timing parameter (in DFI clocks), the maximum cycles between a dfi_rdlvl_req or dfi_rdlvl_gate_req assertion and a dfi_rdlvl_en or dfi_rdlvl_gate_en assertion.
0x68C DDRSS_CTL_419
  [16] RDLVL_GATE_EN — Enable the MC gate training module.
  [8] RDLVL_EN — Enable the MC data eye training module.
  [7:0] RDLVL_RESP_MASK — Mask for the dfi_rdlvl_resp signal during data eye training.
0x690 DDRSS_CTL_420
  [31:0] TDFI_RDLVL_MAX — Defines the DFI tRDLVL_MAX timing parameter (in DFI clocks), the maximum cycles between a dfi_rdlvl_en or dfi_rdlvl_gate_en assertion and a valid dfi_rdlvl_resp.
0x694 DDRSS_CTL_421 access per field
  [23:16] TDFI_CALVL_EN rw — Defines the DFI tCALVL_EN timing parameter (in DFI clocks), the minimum cycles between a dfi_calvl_en assertion and a dfi_cke de-assertion.
  [10:8] RDLVL_GATE_ERROR_STATUS ro — Holds the error associated with the read gate training error or gate training error interrupt.
  [2:0] RDLVL_ERROR_STATUS ro — Holds the error associated with the data eye training error or gate training error interrupt.
{0x0+4i} DDRSS_CTL_{i} (i=422..424)
  [25:16] TDFI_CALVL_CAPTURE_F{i-422} — Defines the DFI tCALVL_CAPTURE timing parameter (in DFI clocks), the minimum cycles between a calibration command and a dfi_calvl_capture pulse.
  [9:0] TDFI_CALVL_CC_F{i-422} — Defines the DFI tCALVL_CC timing parameter (in DFI clocks), the minimum cycles between calibration commands.
0x6A4 DDRSS_CTL_425
  [31:0] TDFI_CALVL_RESP — Defines the DFI tCALVL_RESP timing parameter (in DFI clocks), the maximum cycles between a dfi_calvl_req assertion and a dfi_calvl_en assertion.
0x6A8 DDRSS_CTL_426
  [31:0] TDFI_CALVL_MAX — Defines the DFI tCALVL_MAX timing parameter (in DFI clocks), the maximum cycles between a dfi_calvl_en assertion and a valid dfi_calvl_resp.
0x6AC DDRSS_CTL_427 access per field reset 0x1000000
  [26:24] TDFI_PHY_WRDATA_F0 rw — Defines the DFI tPHY_WRDATA timing parameter (in DFI PHY clocks), the maximum cycles between a dfi_wrdata_en assertion and a dfi_wrdata signal.
  [19:16] CALVL_ERROR_STATUS ro — Holds the error associated with the CA training error interrupt.
  [8] CALVL_EN rw — Enable the MC CA training module.
  [0] CALVL_RESP_MASK rw — Mask for the dfi_calvl_resp signal during CA training.
0x6B0 DDRSS_CTL_428 reset 0x101
  [30:24] TDFI_WRCSLAT_F0 — Defines the DFI tPHY_WRCSLAT timing parameter (in DFI PHY clocks), the maximum cycles between a write command and a dfi_wrdata_cs_n assertion.
  [22:16] TDFI_RDCSLAT_F0 — Defines the DFI tPHY_RDCSLAT timing parameter (in DFI PHY clocks), the maximum cycles between a read command and a dfi_rddata_cs_n assertion.
  [10:8] TDFI_PHY_WRDATA_F2 — Defines the DFI tPHY_WRDATA timing parameter (in DFI PHY clocks), the maximum cycles between a dfi_wrdata_en assertion and a dfi_wrdata signal.
  [2:0] TDFI_PHY_WRDATA_F1 — Defines the DFI tPHY_WRDATA timing parameter (in DFI PHY clocks), the maximum cycles between a dfi_wrdata_en assertion and a dfi_wrdata signal.
0x6B4 DDRSS_CTL_429
  [30:24] TDFI_WRCSLAT_F2 — Defines the DFI tPHY_WRCSLAT timing parameter (in DFI PHY clocks), the maximum cycles between a write command and a dfi_wrdata_cs_n assertion.
  [22:16] TDFI_RDCSLAT_F2 — Defines the DFI tPHY_RDCSLAT timing parameter (in DFI PHY clocks), the maximum cycles between a read command and a dfi_rddata_cs_n assertion.
  [14:8] TDFI_WRCSLAT_F1 — Defines the DFI tPHY_WRCSLAT timing parameter (in DFI PHY clocks), the maximum cycles between a write command and a dfi_wrdata_cs_n assertion.
  [6:0] TDFI_RDCSLAT_F1 — Defines the DFI tPHY_RDCSLAT timing parameter (in DFI PHY clocks), the maximum cycles between a read command and a dfi_rddata_cs_n assertion.
0x6B8 DDRSS_CTL_430
  [24] BL_ON_FLY_ENABLE — Enables the burst length on the fly feature.
  [16] DISABLE_MEMORY_MASKED_WRITE — Restricts the controller from masked write commands.
  [8] EN_1T_TIMING — Enable 1T timing in a system supporting both 1T and 2T timing.
  [7:0] TDFI_WRDATA_DELAY — Defines the tWRDATA_DELAY timing parameter (in DFI PHY clocks), the maximum cycles between when the dfi_wrdata_en signal is asserted and when the corresponding write data transfer is completed on the DRAM bus.
0x6D4 DDRSS_CTL_437 reset 0x200
  [31:24] GLOBAL_ERROR_INFO — Indicates the source of DDR controller safety error interrupts.
0x6D8 DDRSS_CTL_438 access per field reset 0x28280000
  [31:24] NWR_F1 rw — DRAM NWR value in cycles for chip select 2.
  [23:16] NWR_F0 rw — DRAM NWR value in cycles for chip select 2.
  [9:8] AXI_PARITY_ERROR_STATUS ro — Specifies the source of the GLOBAL_ERROR_INFO bit (3) error.
  [7:0] GLOBAL_ERROR_MASK rw — Mask for the DDR0_DDRSS_CONTROLLER_GLOBAL_ERROR_FATAL_0 and DDR0_DDRSS_CONTROLLER_GLOBAL_ERROR_NONFATAL_0 signals from the GLOBAL_ERROR_INFO parameter.
0x6DC DDRSS_CTL_439 access per field reset 0x28
  [20:16] REGPORT_PARAM_PARITY_PROTECTION_STATUS ro — Specifies the source of the GLOBAL_ERROR_INFO bit (5) error.
  [7:0] NWR_F2 rw — DRAM NWR value in cycles for chip select 2.
0x6E0 DDRSS_CTL_440
  [31:0] MC_PARITY_INJECTION_BYTE_ENABLE_0 — Enables a parity error injection on the assocated byte.
0x6E4 DDRSS_CTL_441
  [31:0] MC_PARITY_INJECTION_BYTE_ENABLE_1 — Enables a parity error injection on the assocated byte.
0x6E8 DDRSS_CTL_442
  [24] REGPORT_WRITE_PARITY_PROTECTION_EN — Enables regport write data parity checking from the regport to the param block.
  [16] REGPORT_WRITEMASK_PARITY_PROTECTION_EN — Enables regport write data mask parity checking from the regport to the param block.
  [8] REGPORT_ADDR_PARITY_PROTECTION_EN — Enables regport address/command parity checking from the regport to the param block.
  [0] MC_PARITY_ERROR_TYPE — Defines if the parity error injected is a transient (one-time) or stuck-at (every time) error.
0x6EC DDRSS_CTL_443
  [24] REGPORT_WRITEMASK_PARITY_PROTECTION_INJECTION_EN — Enables regport write mask data parity error injection from the regport to the param block.
  [16] REGPORT_ADDR_PARITY_PROTECTION_INJECTION_EN — Enables regport address/command parity error injection from the regport to the param block.
  [8] PARAMREG_PARITY_PROTECTION_EN — Enables parity checking on the param registers.
  [0] REGPORT_READ_PARITY_PROTECTION_EN — Enables regport read data parity checking from the param block to the regport.
0x6F0 DDRSS_CTL_444
  [16] PARAMREG_PARITY_PROTECTION_INJECTION_EN — Enables parity error injection on the param registers.
  [8] REGPORT_READ_PARITY_PROTECTION_INJECTION_EN — Enables regport read data parity error injection from the param block to the regport.
  [0] REGPORT_WRITE_PARITY_PROTECTION_INJECTION_EN — Enables regport write data parity error injection from the regport to the param block.
0x6FC DDRSS_CTL_447 access per field
  [8] PORT_TO_CORE_PROTECTION_EN rw — Enables parity checking and logic replication protection from the port to the controller core.
0x700 DDRSS_CTL_448
  [31:0] PORT_TO_CORE_PROTECTION_INJECTION_EN_0 — Enables parity error injection from the port to the controller core.
0x704 DDRSS_CTL_449
  [31:0] PORT_TO_CORE_PROTECTION_INJECTION_EN_1 — Enables parity error injection from the port to the controller core.
0x708 DDRSS_CTL_450
  [2:0] PORT_TO_CORE_PROTECTION_INJECTION_EN_2 — Enables parity error injection from the port to the controller core.
{0x0+4i} DDRSS_CTL_{i} (i=455..457)
  [31:0] PORT_TO_CORE_LR_ERR_INJ_EN_{i-455} — Enables error injection from the port to the controller core.
0x728 DDRSS_CTL_458
  [3:0] PORT_TO_CORE_LR_ERR_INJ_EN_3 — Enables error injection from the port to the controller core.
